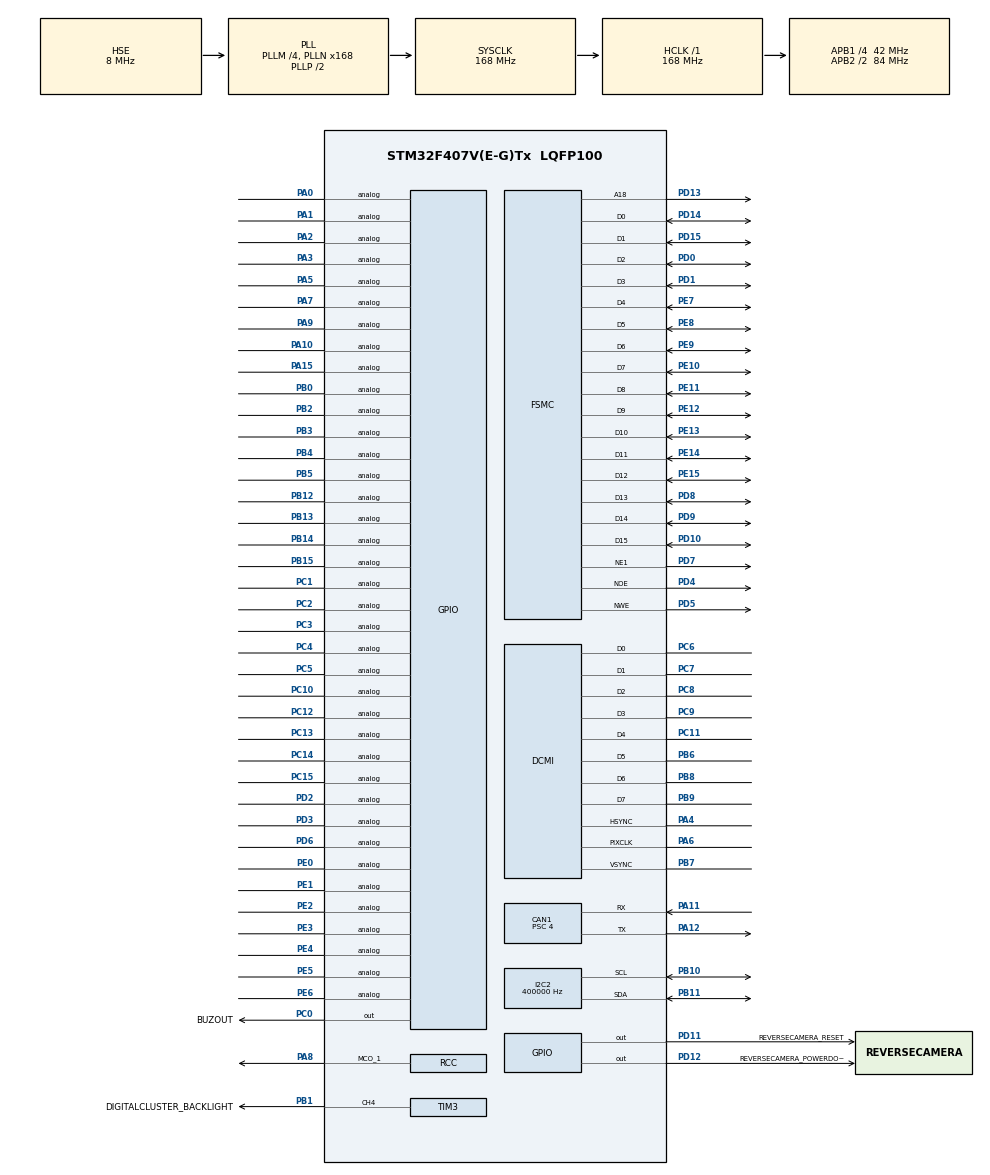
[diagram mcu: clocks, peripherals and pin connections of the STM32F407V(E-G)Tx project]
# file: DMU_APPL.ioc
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CAN1.ABOM=ENABLE
CAN1.AWUM=ENABLE
CAN1.BS1=CAN_BS1_16TQ
CAN1.BS2=CAN_BS2_4TQ
CAN1.CalculateBaudRate=500000
CAN1.CalculateTimeBit=2000
CAN1.CalculateTimeQuantum=95.23809523809524
CAN1.NART=ENABLE
CAN1.Prescaler=4
CAN1.RFLM=ENABLE
CAN1.TTCM=ENABLE
CAN1.TXFP=ENABLE
DCMI.CaptureRate=DCMI_CR_ALL_FRAME
DCMI.JPEGMode=DCMI_JPEG_DISABLE
DCMI.PCKPolarity=DCMI_PCKPOLARITY_RISING
DCMI.VSPolarity=DCMI_VSPOLARITY_HIGH
Dma.DCMI.0.Direction=DMA_PERIPH_TO_MEMORY
Dma.DCMI.0.FIFOMode=DMA_FIFOMODE_DISABLE
Dma.DCMI.0.Instance=DMA2_Stream7
Dma.DCMI.0.MemDataAlignment=DMA_MDATAALIGN_WORD
Dma.DCMI.0.MemInc=DMA_MINC_ENABLE
Dma.DCMI.0.Mode=DMA_CIRCULAR
Dma.DCMI.0.PeriphDataAlignment=DMA_PDATAALIGN_WORD
Dma.DCMI.0.PeriphInc=DMA_PINC_DISABLE
Dma.DCMI.0.Priority=DMA_PRIORITY_VERY_HIGH
Dma.Request0=DCMI
FREERTOS.HEAP_NUMBER=4
FREERTOS.INCLUDE_pcTaskGetTaskName=1
FREERTOS.INCLUDE_uxTaskGetStackHighWaterMark2=1
FREERTOS.INCLUDE_vTaskCleanUpResources=1
FREERTOS.INCLUDE_xEventGroupSetBitFromISR=1
FREERTOS.INCLUDE_xSemaphoreGetMutexHolder=1
FREERTOS.INCLUDE_xTaskAbortDelay=1
FREERTOS.INCLUDE_xTaskGetHandle=1
FREERTOS.Tasks01=QM_APPL,10,1024,QM_APPL_OS_TASK,Default,NULL,Dynamic,NULL,NULL;QM_BSW,55,256,QM_BSW_OS_TASK,Default,NULL,Dynamic,NULL,NULL;NVM_HANDLING,9,128,NVM_HANDLING_OS_TASK,Default,NULL,Dynamic,NULL,NULL;QM_DCM,54,128,OS_TASK_QM_DCM,Default,NULL,Dynamic,NULL,NULL
FREERTOS.Timers01=Alarm5ms_QM_APPL,Alarm5ms_QM_APPL_Callback,osTimerPeriodic,Default,NULL,Dynamic,NULL;Alarm5ms_QM_BSW,Alarm5ms_QM_BSW_Callback,osTimerPeriodic,Default,NULL,Dynamic,NULL;Alarm10ms_QM_APPL,Alarm10ms_QM_APPL_Callback,osTimerPeriodic,Default,NULL,Dynamic,NULL;Alarm10ms_QM_BSW,Alarm10ms_QM_BSW_Callback,osTimerPeriodic,Default,NULL,Dynamic,NULL
FREERTOS.configCHECK_FOR_STACK_OVERFLOW=1
FREERTOS.configENABLE_BACKWARD_COMPATIBILITY=1
FREERTOS.configENABLE_FPU=0
FREERTOS.configGENERATE_RUN_TIME_STATS=0
FREERTOS.configLIBRARY_MAX_SYSCALL_INTERRUPT_PRIORITY=1
FREERTOS.configMAX_TASK_NAME_LEN=255
FREERTOS.configQUEUE_REGISTRY_SIZE=255
FREERTOS.configRECORD_STACK_HIGH_ADDRESS=1
FREERTOS.configTIMER_QUEUE_LENGTH=10
FREERTOS.configTIMER_TASK_PRIORITY=55
FREERTOS.configTIMER_TASK_STACK_DEPTH=128
FREERTOS.configTOTAL_HEAP_SIZE=12000
FREERTOS.configUSE_APPLICATION_TASK_TAG=0
FREERTOS.configUSE_CO_ROUTINES=0
FREERTOS.configUSE_DAEMON_TASK_STARTUP_HOOK=0
FREERTOS.configUSE_IDLE_HOOK=1
FREERTOS.configUSE_MALLOC_FAILED_HOOK=1
FREERTOS.configUSE_NEWLIB_REENTRANT=1
FREERTOS.configUSE_POSIX_ERRNO=0
FREERTOS.configUSE_STATS_FORMATTING_FUNCTIONS=0
FREERTOS.configUSE_TASK_NOTIFICATIONS=1
FREERTOS.configUSE_TICKLESS_IDLE=0
FREERTOS.configUSE_TICK_HOOK=1
FREERTOS.configUSE_TRACE_FACILITY=1
FSMC.AddressSetupTime1=1
FSMC.BusTurnAroundDuration1=0
FSMC.DataSetupTime1=5
FSMC.ExtendedMode1=FSMC_EXTENDED_MODE_DISABLE
I2C2.ClockSpeed=400000
I2C2.I2C_Mode=I2C_Fast
Mcu.Family=STM32F4
Mcu.Name=STM32F407V(E-G)Tx
Mcu.Package=LQFP100
NVIC.CAN1_RX0_IRQn=true\:8\:0\:true\:true\:true\:5\:true\:true\:true\:true
NVIC.CAN1_RX1_IRQn=true\:9\:0\:true\:true\:true\:6\:true\:true\:true\:true
NVIC.CAN1_SCE_IRQn=true\:12\:0\:true\:true\:true\:8\:true\:true\:true\:true
NVIC.CAN1_TX_IRQn=true\:10\:0\:true\:true\:true\:7\:true\:true\:true\:true
NVIC.DCMI_IRQn=true\:7\:0\:true\:true\:true\:4\:true\:true\:true\:true
NVIC.DMA2_Stream7_IRQn=true\:1\:0\:false\:true\:true\:12\:true\:false\:true\:true
NVIC.FLASH_IRQn=true\:3\:0\:true\:true\:true\:1\:true\:true\:true\:true
NVIC.FPU_IRQn=true\:15\:0\:true\:true\:true\:2\:true\:true\:false\:true
NVIC.I2C2_ER_IRQn=true\:1\:0\:false\:true\:true\:11\:true\:true\:true\:true
NVIC.I2C2_EV_IRQn=true\:1\:0\:false\:true\:true\:10\:true\:true\:true\:true
NVIC.PVD_IRQn=true\:15\:0\:true\:true\:true\:3\:true\:true\:true\:true
NVIC.PriorityGroup=NVIC_PRIORITYGROUP_4
NVIC.RCC_IRQn=true\:1\:0\:false\:true\:true\:9\:true\:true\:false\:true
NVIC.TIM1_UP_TIM10_IRQn=true\:15\:0\:false\:false\:true\:false\:false\:true\:true
NVIC.TIM3_IRQn=true\:1\:0\:false\:true\:true\:13\:true\:true\:true\:true
NVIC.TimeBase=TIM1_UP_TIM10_IRQn
NVIC.TimeBaseIP=TIM1
PA0-WKUP.Signal=GPIO_Analog
PA1.Signal=GPIO_Analog
PA10.Signal=GPIO_Analog
PA11.Mode=CAN_Activate
PA11.Signal=CAN1_RX
PA12.GPIO_PuPd=GPIO_PULLUP
PA12.Mode=CAN_Activate
PA12.Signal=CAN1_TX
PA13.Mode=Serial_Wire
PA13.Signal=SYS_JTMS-SWDIO
PA14.Mode=Serial_Wire
PA14.Signal=SYS_JTCK-SWCLK
PA15.Signal=GPIO_Analog
PA2.Signal=GPIO_Analog
PA3.Signal=GPIO_Analog
PA4.GPIO_PuPd=GPIO_PULLDOWN
PA4.GPIO_Speed=GPIO_SPEED_FREQ_VERY_HIGH
PA4.Mode=Slave_8_bits_External_Synchro
PA4.Signal=DCMI_HSYNC
PA5.Signal=GPIO_Analog
PA6.GPIO_PuPd=GPIO_PULLDOWN
PA6.GPIO_Speed=GPIO_SPEED_FREQ_VERY_HIGH
PA6.Mode=Slave_8_bits_External_Synchro
PA6.Signal=DCMI_PIXCLK
PA7.Signal=GPIO_Analog
PA8.GPIO_Speed=GPIO_SPEED_FREQ_VERY_HIGH
PA8.Mode=Clock-out-1
PA8.Signal=RCC_MCO_1
PA9.Signal=GPIO_Analog
PB0.Signal=GPIO_Analog
PB1.GPIO_Label=DIGITALCLUSTER_BACKLIGHT
PB1.Signal=S_TIM3_CH4
PB10.GPIO_Pu=GPIO_PULLUP
PB10.Mode=I2C
PB10.Signal=I2C2_SCL
PB11.GPIO_Pu=GPIO_PULLUP
PB11.Mode=I2C
PB11.Signal=I2C2_SDA
PB12.Signal=GPIO_Analog
PB13.Signal=GPIO_Analog
PB14.Signal=GPIO_Analog
PB15.Signal=GPIO_Analog
PB2.Signal=GPIO_Analog
PB3.Signal=GPIO_Analog
PB4.Signal=GPIO_Analog
PB5.Signal=GPIO_Analog
PB6.GPIO_PuPd=GPIO_PULLDOWN
PB6.GPIO_Speed=GPIO_SPEED_FREQ_VERY_HIGH
PB6.Mode=Slave_8_bits_External_Synchro
PB6.Signal=DCMI_D5
PB7.GPIO_PuPd=GPIO_PULLDOWN
PB7.GPIO_Speed=GPIO_SPEED_FREQ_VERY_HIGH
PB7.Mode=Slave_8_bits_External_Synchro
PB7.Signal=DCMI_VSYNC
PB8.GPIO_PuPd=GPIO_PULLDOWN
PB8.GPIO_Speed=GPIO_SPEED_FREQ_VERY_HIGH
PB8.Mode=Slave_8_bits_External_Synchro
PB8.Signal=DCMI_D6
PB9.GPIO_PuPd=GPIO_PULLDOWN
PB9.GPIO_Speed=GPIO_SPEED_FREQ_VERY_HIGH
PB9.Mode=Slave_8_bits_External_Synchro
PB9.Signal=DCMI_D7
PC0.GPIO_Label=BUZOUT
PC0.GPIO_PuPd=GPIO_PULLDOWN
PC0.GPIO_Speed=GPIO_SPEED_FREQ_VERY_HIGH
PC0.Signal=GPIO_Output
PC1.Signal=GPIO_Analog
PC10.Signal=GPIO_Analog
PC11.GPIO_PuPd=GPIO_PULLDOWN
PC11.GPIO_Speed=GPIO_SPEED_FREQ_VERY_HIGH
PC11.Mode=Slave_8_bits_External_Synchro
PC11.Signal=DCMI_D4
PC12.Signal=GPIO_Analog
PC13-ANTI_TAMP.Signal=GPIO_Analog
PC14-OSC32_IN.Signal=GPIO_Analog
PC15-OSC32_OUT.Signal=GPIO_Analog
PC2.Signal=GPIO_Analog
PC3.Signal=GPIO_Analog
PC4.Signal=GPIO_Analog
PC5.Signal=GPIO_Analog
PC6.GPIO_PuPd=GPIO_PULLDOWN
PC6.GPIO_Speed=GPIO_SPEED_FREQ_VERY_HIGH
PC6.Mode=Slave_8_bits_External_Synchro
PC6.Signal=DCMI_D0
PC7.GPIO_PuPd=GPIO_PULLDOWN
PC7.GPIO_Speed=GPIO_SPEED_FREQ_VERY_HIGH
PC7.Mode=Slave_8_bits_External_Synchro
PC7.Signal=DCMI_D1
PC8.GPIO_PuPd=GPIO_PULLDOWN
PC8.GPIO_Speed=GPIO_SPEED_FREQ_VERY_HIGH
PC8.Mode=Slave_8_bits_External_Synchro
PC8.Signal=DCMI_D2
PC9.GPIO_PuPd=GPIO_PULLDOWN
PC9.GPIO_Speed=GPIO_SPEED_FREQ_VERY_HIGH
PC9.Mode=Slave_8_bits_External_Synchro
PC9.Signal=DCMI_D3
PD0.Mode=16b-d1
PD0.Signal=FSMC_D2
PD1.Mode=16b-d1
PD1.Signal=FSMC_D3
PD10.Mode=16b-d1
PD10.Signal=FSMC_D15
PD11.GPIO_Label=REVERSECAMERA_RESET
PD11.Signal=GPIO_Output
PD12.GPIO_Label=REVERSECAMERA_POWERDOWN
PD12.Signal=GPIO_Output
PD13.Mode=A18_1
PD13.Signal=FSMC_A18
PD14.Mode=16b-d1
PD14.Signal=FSMC_D0
PD15.Mode=16b-d1
PD15.Signal=FSMC_D1
PD2.Signal=GPIO_Analog
PD3.Signal=GPIO_Analog
PD4.GPIO_PuPd=GPIO_PULLUP
PD4.GPIO_Speed_High_Default=GPIO_SPEED_FREQ_VERY_HIGH
PD4.Mode=Lcd1
PD4.Signal=FSMC_NOE
PD5.GPIO_PuPd=GPIO_PULLUP
PD5.GPIO_Speed_High_Default=GPIO_SPEED_FREQ_VERY_HIGH
PD5.Mode=Lcd1
PD5.Signal=FSMC_NWE
PD6.Signal=GPIO_Analog
PD7.GPIO_PuPd=GPIO_PULLUP
PD7.GPIO_Speed_High_Default=GPIO_SPEED_FREQ_VERY_HIGH
PD7.Mode=NorPsramChipSelect1_1
PD7.Signal=FSMC_NE1
PD8.Mode=16b-d1
PD8.Signal=FSMC_D13
PD9.Mode=16b-d1
PD9.Signal=FSMC_D14
PE0.Signal=GPIO_Analog
PE1.Signal=GPIO_Analog
PE10.Mode=16b-d1
PE10.Signal=FSMC_D7
PE11.Mode=16b-d1
PE11.Signal=FSMC_D8
PE12.Mode=16b-d1
PE12.Signal=FSMC_D9
PE13.Mode=16b-d1
PE13.Signal=FSMC_D10
PE14.Mode=16b-d1
PE14.Signal=FSMC_D11
PE15.Mode=16b-d1
PE15.Signal=FSMC_D12
PE2.Signal=GPIO_Analog
PE3.Signal=GPIO_Analog
PE4.Signal=GPIO_Analog
PE5.Signal=GPIO_Analog
PE6.Signal=GPIO_Analog
PE7.Mode=16b-d1
PE7.Signal=FSMC_D4
PE8.Mode=16b-d1
PE8.Signal=FSMC_D5
PE9.Mode=16b-d1
PE9.Signal=FSMC_D6
PH0-OSC_IN.Mode=HSE-External-Oscillator
PH0-OSC_IN.Signal=RCC_OSC_IN
PH1-OSC_OUT.Mode=HSE-External-Oscillator
PH1-OSC_OUT.Signal=RCC_OSC_OUT
ProjectManager.HeapSize=0x200
ProjectManager.StackSize=0x200
ProjectManager.TargetToolchain=STM32CubeIDE
RCC.48MHZClocksFreq_Value=84000000
RCC.AHBFreq_Value=168000000
RCC.APB1CLKDivider=RCC_HCLK_DIV4
RCC.APB1Freq_Value=42000000
RCC.APB1TimFreq_Value=84000000
RCC.APB2CLKDivider=RCC_HCLK_DIV2
RCC.APB2Freq_Value=84000000
RCC.APB2TimFreq_Value=168000000
RCC.CortexFreq_Value=168000000
RCC.EnbaleCSS=true
RCC.HCLKFreq_Value=168000000
RCC.HSE_VALUE=8000000
RCC.HSI_VALUE=16000000
RCC.LSE_VALUE=32768
RCC.PLLM=4
RCC.PLLN=168
RCC.PLLSourceVirtual=RCC_PLLSOURCE_HSE
RCC.RCC_MCO1Source=RCC_MCO1SOURCE_PLLCLK
RCC.RCC_MCODiv1=RCC_MCODIV_5
RCC.RCC_RTC_Clock_Source_FROM_HSE=RCC_RTCCLKSOURCE_HSE_DIV31
RCC.SYSCLKFreq_VALUE=168000000
RCC.SYSCLKSource=RCC_SYSCLKSOURCE_PLLCLK
RCC.VCOOutputFreq_Value=336000000
RCC.VDD_VALUE=3.6
RTC.Date=11
RTC.Hours=12
RTC.Month=RTC_MONTH_SEPTEMBER
RTC.StoreOperation=RTC_STOREOPERATION_SET
SH.S_TIM3_CH4.0=TIM3_CH4,PWM Generation4 CH4
STMicroelectronics.X-CUBE-DISPLAY.3.0.0.p_display_big_endian=false
STMicroelectronics.X-CUBE-DISPLAY.3.0.0.p_display_swap_rb=false
STMicroelectronics.X-CUBE-DISPLAY.3.0.0.p_display_te_event_source=TE_SRC_DISABLED
STMicroelectronics.X-CUBE-DISPLAY.3.0.0.p_fmc_dma_instance_name=DMA1_Channel1
STMicroelectronics.X-CUBE-DISPLAY.3.0.0_IsPackSelfContextualization=true
STMicroelectronics.X-CUBE-TOUCHGFX.4.23.2_IsPackSelfContextualization=true
TIM3.Channel-PWM\ Generation4\ CH4=TIM_CHANNEL_4
TIM3.Period=9999
TIM3.Prescaler=167
VP_FREERTOS_VS_CMSIS_V2.Mode=CMSIS_V2
VP_RTC_VS_RTC_Activate.Mode=RTC_Enabled
VP_RTC_VS_RTC_Calendar.Mode=RTC_Calendar
VP_SYS_VS_tim1.Mode=TIM1
board=custom

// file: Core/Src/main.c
/* USER CODE BEGIN Header */
/* USER CODE END Header */
#include "main.h"
#include "cmsis_os.h"
#include "can.h"
#include "dcmi.h"
#include "dma.h"
#include "i2c.h"
#include "rtc.h"
#include "tim.h"
#include "gpio.h"
#include "fsmc.h"

/* USER CODE BEGIN Includes */
#include "Std_Types.h"
#include <stdbool.h>
/* USER CODE END Includes */

/* USER CODE BEGIN PV */
extern bool Nvm_Init_Status;
/* USER CODE END PV */

void SystemClock_Config(void);
void MX_FREERTOS_Init(void);
static void MX_NVIC_Init(void);
/* USER CODE BEGIN PFP */
extern bool Nvm_W25Q16_Init(void);
/* USER CODE END PFP */

/* USER CODE BEGIN 0 */
extern void EcuM_PerformReset(uint8 param);
/* USER CODE END 0 */

int main(void)
{

  /* MCU Configuration--------------------------------------------------------*/

  /* Reset of all peripherals, Initializes the Flash interface and the Systick. */
  HAL_Init();

  /* Configure the system clock */
  SystemClock_Config();

  /* USER CODE BEGIN SysInit */
	HAL_PWR_EnableBkUpAccess();
  /* USER CODE END SysInit */

  /* Initialize all configured peripherals */
  MX_DMA_Init();
  MX_GPIO_Init();
  MX_CAN1_Init();
  MX_DCMI_Init();
  MX_FSMC_Init();
  MX_RTC_Init();
  MX_I2C2_Init();
  MX_TIM3_Init();

  /* Initialize interrupts */
  MX_NVIC_Init();
  /* USER CODE BEGIN 2 */
  HAL_TIM_PWM_Start(&htim3, TIM_CHANNEL_4);
  /* USER CODE END 2 */

  /* Init scheduler */
  osKernelInitialize();

  /* Call init function for freertos objects (in cmsis_os2.c) */
  MX_FREERTOS_Init();

  /* Start scheduler */
  osKernelStart();

  /* We should never get here as control is now taken by the scheduler */

  /* Infinite loop */
  /* USER CODE BEGIN WHILE */
	EcuM_PerformReset(4);
	while (1)
	{
    /* USER CODE END WHILE */

	}
}

void SystemClock_Config(void)
{
  RCC_OscInitTypeDef RCC_OscInitStruct = {0};
  RCC_ClkInitTypeDef RCC_ClkInitStruct = {0};

  /** Configure the main internal regulator output voltage
  */
  __HAL_RCC_PWR_CLK_ENABLE();
  __HAL_PWR_VOLTAGESCALING_CONFIG(PWR_REGULATOR_VOLTAGE_SCALE1);

  /** Initializes the RCC Oscillators according to the specified parameters
  * in the RCC_OscInitTypeDef structure.
  */
  RCC_OscInitStruct.OscillatorType = RCC_OSCILLATORTYPE_LSI|RCC_OSCILLATORTYPE_HSE;
  RCC_OscInitStruct.HSEState = RCC_HSE_ON;
  RCC_OscInitStruct.LSIState = RCC_LSI_ON;
  RCC_OscInitStruct.PLL.PLLState = RCC_PLL_ON;
  RCC_OscInitStruct.PLL.PLLSource = RCC_PLLSOURCE_HSE;
  RCC_OscInitStruct.PLL.PLLM = 4;
  RCC_OscInitStruct.PLL.PLLN = 168;
  RCC_OscInitStruct.PLL.PLLP = RCC_PLLP_DIV2;
  RCC_OscInitStruct.PLL.PLLQ = 4;
  if (HAL_RCC_OscConfig(&RCC_OscInitStruct) != HAL_OK)
  {
    Error_Handler();
  }

  /** Initializes the CPU, AHB and APB buses clocks
  */
  RCC_ClkInitStruct.ClockType = RCC_CLOCKTYPE_HCLK|RCC_CLOCKTYPE_SYSCLK
                              |RCC_CLOCKTYPE_PCLK1|RCC_CLOCKTYPE_PCLK2;
  RCC_ClkInitStruct.SYSCLKSource = RCC_SYSCLKSOURCE_PLLCLK;
  RCC_ClkInitStruct.AHBCLKDivider = RCC_SYSCLK_DIV1;
  RCC_ClkInitStruct.APB1CLKDivider = RCC_HCLK_DIV4;
  RCC_ClkInitStruct.APB2CLKDivider = RCC_HCLK_DIV2;

  if (HAL_RCC_ClockConfig(&RCC_ClkInitStruct, FLASH_LATENCY_5) != HAL_OK)
  {
    Error_Handler();
  }
  HAL_RCC_MCOConfig(RCC_MCO1, RCC_MCO1SOURCE_PLLCLK, RCC_MCODIV_5);

  /** Enables the Clock Security System
  */
  HAL_RCC_EnableCSS();
}

/**
  * @brief NVIC Configuration.
  * @retval None
  */
static void MX_NVIC_Init(void)
{
  /* FLASH_IRQn interrupt configuration */
  HAL_NVIC_SetPriority(FLASH_IRQn, 3, 0);
  HAL_NVIC_EnableIRQ(FLASH_IRQn);
  /* FPU_IRQn interrupt configuration */
  HAL_NVIC_SetPriority(FPU_IRQn, 15, 0);
  HAL_NVIC_EnableIRQ(FPU_IRQn);
  /* PVD_IRQn interrupt configuration */
  HAL_NVIC_SetPriority(PVD_IRQn, 15, 0);
  HAL_NVIC_EnableIRQ(PVD_IRQn);
  /* DCMI_IRQn interrupt configuration */
  HAL_NVIC_SetPriority(DCMI_IRQn, 7, 0);
  HAL_NVIC_EnableIRQ(DCMI_IRQn);
  /* CAN1_RX0_IRQn interrupt configuration */
  HAL_NVIC_SetPriority(CAN1_RX0_IRQn, 8, 0);
  HAL_NVIC_EnableIRQ(CAN1_RX0_IRQn);
  /* CAN1_RX1_IRQn interrupt configuration */
  HAL_NVIC_SetPriority(CAN1_RX1_IRQn, 9, 0);
  HAL_NVIC_EnableIRQ(CAN1_RX1_IRQn);
  /* CAN1_TX_IRQn interrupt configuration */
  HAL_NVIC_SetPriority(CAN1_TX_IRQn, 10, 0);
  HAL_NVIC_EnableIRQ(CAN1_TX_IRQn);
  /* CAN1_SCE_IRQn interrupt configuration */
  HAL_NVIC_SetPriority(CAN1_SCE_IRQn, 12, 0);
  HAL_NVIC_EnableIRQ(CAN1_SCE_IRQn);
  /* RCC_IRQn interrupt configuration */
  HAL_NVIC_SetPriority(RCC_IRQn, 1, 0);
  HAL_NVIC_EnableIRQ(RCC_IRQn);
  /* I2C2_EV_IRQn interrupt configuration */
  HAL_NVIC_SetPriority(I2C2_EV_IRQn, 1, 0);
  HAL_NVIC_EnableIRQ(I2C2_EV_IRQn);
  /* I2C2_ER_IRQn interrupt configuration */
  HAL_NVIC_SetPriority(I2C2_ER_IRQn, 1, 0);
  HAL_NVIC_EnableIRQ(I2C2_ER_IRQn);
  /* DMA2_Stream7_IRQn interrupt configuration */
  HAL_NVIC_SetPriority(DMA2_Stream7_IRQn, 1, 0);
  HAL_NVIC_EnableIRQ(DMA2_Stream7_IRQn);
  /* TIM3_IRQn interrupt configuration */
  HAL_NVIC_SetPriority(TIM3_IRQn, 1, 0);
  HAL_NVIC_EnableIRQ(TIM3_IRQn);
}

void HAL_TIM_PeriodElapsedCallback(TIM_HandleTypeDef *htim)
{
  if (htim->Instance == TIM1)
  {
    HAL_IncTick();
  }
}

void Error_Handler(void)
{
  /* USER CODE BEGIN Error_Handler_Debug */
	EcuM_PerformReset(3);
  /* USER CODE END Error_Handler_Debug */
}

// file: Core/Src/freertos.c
/* USER CODE BEGIN Header */
/* USER CODE END Header */

#include "FreeRTOS.h"
#include "task.h"
#include "main.h"
#include "cmsis_os.h"

/* USER CODE BEGIN Includes */
#include "event_groups.h"
#include "DigitalCluster.h"
#include "DataRecorder.h"
#include "RevCam.h"
#include "CanH.h"
#include "I2cH.h"
#include "Dcm.h"
#include "Dem.h"
#include "Nvm.h"
#include "EcuM.h"
#include "FsmcH.h"
#include "DcmiH_OV7670.h"
/* USER CODE END Includes */

/* USER CODE BEGIN Variables */
__attribute__((section(".ccmram"))) long long OS_Counter = 0;
__attribute__((section(".ccmram"))) long long IDLE_Counter = 0;
__attribute__((section(".ccmram"))) uint8 Alarm5ms_QM_NVM = 0;
__attribute__((section(".ccmram"))) uint8 Alarm5ms_QM_APPL = 0;
__attribute__((section(".ccmram"))) uint8 Alarm5ms_QM_BSW = 0;
__attribute__((section(".ccmram"))) uint8 Alarm5ms_QM_DCM = 0;
__attribute__((section(".ccmram"))) uint8 Alarm10ms_QM_APPL = 0;
__attribute__((section(".ccmram"))) uint8 Alarm10ms_QM_BSW = 0;
extern __attribute__((section(".ccmram"))) uint8 EcuM_State;
extern __attribute__((section(".ccmram"))) uint8 Nvm_ReadAllPending;
extern TIM_HandleTypeDef htim9;
/* USER CODE END Variables */
/* Definitions for QM_APPL */
osThreadId_t QM_APPLHandle;
const osThreadAttr_t QM_APPL_attributes = {
  .name = "QM_APPL",
  .stack_size = 1024 * 4,
  .priority = (osPriority_t) osPriorityLow2,
};
/* Definitions for QM_BSW */
osThreadId_t QM_BSWHandle;
const osThreadAttr_t QM_BSW_attributes = {
  .name = "QM_BSW",
  .stack_size = 256 * 4,
  .priority = (osPriority_t) osPriorityRealtime7,
};
/* Definitions for NVM_HANDLING */
osThreadId_t NVM_HANDLINGHandle;
const osThreadAttr_t NVM_HANDLING_attributes = {
  .name = "NVM_HANDLING",
  .stack_size = 128 * 4,
  .priority = (osPriority_t) osPriorityLow1,
};
/* Definitions for QM_DCM */
osThreadId_t QM_DCMHandle;
const osThreadAttr_t QM_DCM_attributes = {
  .name = "QM_DCM",
  .stack_size = 128 * 4,
  .priority = (osPriority_t) osPriorityRealtime6,
};
/* Definitions for Alarm5ms_QM_APPL */
osTimerId_t Alarm5ms_QM_APPLHandle;
const osTimerAttr_t Alarm5ms_QM_APPL_attributes = {
  .name = "Alarm5ms_QM_APPL"
};
/* Definitions for Alarm5ms_QM_BSW */
osTimerId_t Alarm5ms_QM_BSWHandle;
const osTimerAttr_t Alarm5ms_QM_BSW_attributes = {
  .name = "Alarm5ms_QM_BSW"
};
/* Definitions for Alarm10ms_QM_APPL */
osTimerId_t Alarm10ms_QM_APPLHandle;
const osTimerAttr_t Alarm10ms_QM_APPL_attributes = {
  .name = "Alarm10ms_QM_APPL"
};
/* Definitions for Alarm10ms_QM_BSW */
osTimerId_t Alarm10ms_QM_BSWHandle;
const osTimerAttr_t Alarm10ms_QM_BSW_attributes = {
  .name = "Alarm10ms_QM_BSW"
};

/* USER CODE BEGIN FunctionPrototypes */
extern void EcuM_PerformReset(uint8 param);
/* USER CODE END FunctionPrototypes */

void QM_APPL_OS_TASK(void *argument);
void QM_BSW_OS_TASK(void *argument);
void NVM_HANDLING_OS_TASK(void *argument);
void OS_TASK_QM_DCM(void *argument);
void Alarm5ms_QM_APPL_Callback(void *argument);
void Alarm5ms_QM_BSW_Callback(void *argument);
void Alarm10ms_QM_APPL_Callback(void *argument);
void Alarm10ms_QM_BSW_Callback(void *argument);

void MX_FREERTOS_Init(void); /* (MISRA C 2004 rule 8.1) */

/* Hook prototypes */
void vApplicationIdleHook(void);
void vApplicationTickHook(void);
void vApplicationStackOverflowHook(xTaskHandle xTask, signed char *pcTaskName);
void vApplicationMallocFailedHook(void);

/* USER CODE BEGIN 2 */
void vApplicationIdleHook( void )
{
	IDLE_Counter++;
}
/* USER CODE END 2 */

/* USER CODE BEGIN 3 */
void vApplicationTickHook( void )
{
	OS_Counter++;
}
/* USER CODE END 3 */

/* USER CODE BEGIN 4 */
void vApplicationStackOverflowHook(xTaskHandle xTask, signed char *pcTaskName)
{
	EcuM_PerformReset(12);
}
/* USER CODE END 4 */

/* USER CODE BEGIN 5 */
void vApplicationMallocFailedHook(void)
{
	EcuM_PerformReset(11);
}
/* USER CODE END 5 */

void MX_FREERTOS_Init(void) {

  /* Create the timer(s) */
  /* creation of Alarm5ms_QM_APPL */
  Alarm5ms_QM_APPLHandle = osTimerNew(Alarm5ms_QM_APPL_Callback, osTimerPeriodic, NULL, &Alarm5ms_QM_APPL_attributes);

  /* creation of Alarm5ms_QM_BSW */
  Alarm5ms_QM_BSWHandle = osTimerNew(Alarm5ms_QM_BSW_Callback, osTimerPeriodic, NULL, &Alarm5ms_QM_BSW_attributes);

  /* creation of Alarm10ms_QM_APPL */
  Alarm10ms_QM_APPLHandle = osTimerNew(Alarm10ms_QM_APPL_Callback, osTimerPeriodic, NULL, &Alarm10ms_QM_APPL_attributes);

  /* creation of Alarm10ms_QM_BSW */
  Alarm10ms_QM_BSWHandle = osTimerNew(Alarm10ms_QM_BSW_Callback, osTimerPeriodic, NULL, &Alarm10ms_QM_BSW_attributes);

  /* Create the thread(s) */
  /* creation of QM_APPL */
  QM_APPLHandle = osThreadNew(QM_APPL_OS_TASK, NULL, &QM_APPL_attributes);

  /* creation of QM_BSW */
  QM_BSWHandle = osThreadNew(QM_BSW_OS_TASK, NULL, &QM_BSW_attributes);

  /* creation of NVM_HANDLING */
  NVM_HANDLINGHandle = osThreadNew(NVM_HANDLING_OS_TASK, NULL, &NVM_HANDLING_attributes);

  /* creation of QM_DCM */
  QM_DCMHandle = osThreadNew(OS_TASK_QM_DCM, NULL, &QM_DCM_attributes);

  /* USER CODE BEGIN RTOS_EVENTS */
	osTimerStart(Alarm10ms_QM_BSWHandle, 10);
	osTimerStart(Alarm5ms_QM_BSWHandle, 5);
	osTimerStart(Alarm10ms_QM_APPLHandle, 10);
	osTimerStart(Alarm5ms_QM_APPLHandle, 5);
  /* USER CODE END RTOS_EVENTS */

}

void QM_APPL_OS_TASK(void *argument)
{
  /* USER CODE BEGIN QM_APPL_OS_TASK */
	for(;;)
	{
		if(1 == Alarm5ms_QM_APPL)
		{
			if(1 == EcuM_State && 2 == Nvm_ReadAllPending) DigitalCluster_MainFunction();
			else
			{
				/* Do nothing. */
			}
			Alarm5ms_QM_APPL = 0;
		}
		else
		{
			/* Do nothing.  */
		}
		if(1 == Alarm10ms_QM_APPL && 2 == Nvm_ReadAllPending)
		{
			DataRecorder_MainFunction();
			Alarm10ms_QM_APPL = 0;
		}
		else
		{
			/* Do nothing.  */
		}
		vTaskSuspend(NULL);
	}
  /* USER CODE END QM_APPL_OS_TASK */
}

void QM_BSW_OS_TASK(void *argument)
{
  /* USER CODE BEGIN QM_BSW_OS_TASK */
	for(;;)
	{
		if(1 == Alarm5ms_QM_BSW)
		{
			EcuM_MainFunction();
			CanH_MainFunction();
			Alarm5ms_QM_BSW = 0;
		}
		else
		{
			/* Do nothing.  */
		}
		if(1 == Alarm10ms_QM_BSW)
		{
			I2cH_MainFunction();
			DcmiH_MainFunction();
			FsmcH_MainFunction();
			if(1 == EcuM_State) Dem_MainFunction();
			else
			{
				/* Do nothing. */
			}
			Alarm10ms_QM_BSW = 0;
		}
		else
		{
			/* Do nothing.  */
		}
		vTaskSuspend(NULL);
	}
  /* USER CODE END QM_BSW_OS_TASK */
}

void NVM_HANDLING_OS_TASK(void *argument)
{
  /* USER CODE BEGIN NVM_HANDLING_OS_TASK */
	for(;;)
	{
		if(1 == Alarm5ms_QM_NVM)
		{
			Nvm_MainFunction();
			Alarm5ms_QM_NVM = 0;
		}
		else
		{
			/* Do nothing.  */
		}
		vTaskSuspend(NULL);
	}
  /* USER CODE END NVM_HANDLING_OS_TASK */
}

void OS_TASK_QM_DCM(void *argument)
{
  /* USER CODE BEGIN OS_TASK_QM_DCM */
	for(;;)
	{
		if(1 == Alarm5ms_QM_DCM)
		{
			if(1 == EcuM_State) Dcm_MainFunction();
			else
			{
				/* Do nothing. */
			}
			Alarm5ms_QM_DCM = 0;
		}
		else
		{
			/* Do nothing. */
		}
		vTaskSuspend(NULL);
	}
  /* USER CODE END OS_TASK_QM_DCM */
}

/* Alarm5ms_QM_APPL_Callback function */
void Alarm5ms_QM_APPL_Callback(void *argument)
{
  /* USER CODE BEGIN Alarm5ms_QM_APPL_Callback */
	vTaskResume(QM_APPLHandle);
	Alarm5ms_QM_APPL = 1;
  /* USER CODE END Alarm5ms_QM_APPL_Callback */
}

/* Alarm5ms_QM_BSW_Callback function */
void Alarm5ms_QM_BSW_Callback(void *argument)
{
  /* USER CODE BEGIN Alarm5ms_QM_BSW_Callback */
	Alarm5ms_QM_BSW = 1;
	Alarm5ms_QM_DCM = 1;
	Alarm5ms_QM_NVM = 1;
	vTaskResume(QM_BSWHandle);
	vTaskResume(QM_DCMHandle);
	vTaskResume(NVM_HANDLINGHandle);
  /* USER CODE END Alarm5ms_QM_BSW_Callback */
}

/* Alarm10ms_QM_APPL_Callback function */
void Alarm10ms_QM_APPL_Callback(void *argument)
{
  /* USER CODE BEGIN Alarm10ms_QM_APPL_Callback */
	Alarm10ms_QM_APPL = 1;
	vTaskResume(QM_APPLHandle);
  /* USER CODE END Alarm10ms_QM_APPL_Callback */
}

/* Alarm10ms_QM_BSW_Callback function */
void Alarm10ms_QM_BSW_Callback(void *argument)
{
  /* USER CODE BEGIN Alarm10ms_QM_BSW_Callback */
	Alarm10ms_QM_BSW = 1;
	vTaskResume(QM_BSWHandle);
  /* USER CODE END Alarm10ms_QM_BSW_Callback */
}
